# STM32F429 register map
File version: 1.8
CPU: CM4 r0p1, little endian, MPU, FPU, 4 interrupt priority bits
Registers are 32-bit, read-write, reset 0x0 unless marked. A register's access mark holds for its fields unless they carry their own. Offsets are from the block's base; [hi:lo] are bit positions; {n}, {i} and the like mark numbered series.

## I2C1 — Inter-integrated circuit
Base 0x40005400
Same registers: I2C2 0x40005800, I2C3 0x40005C00
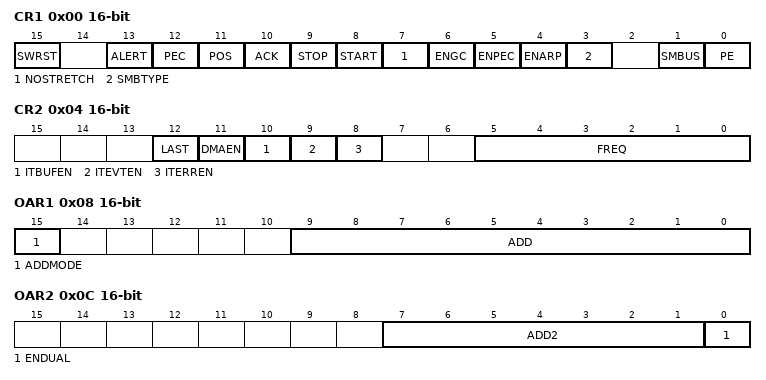
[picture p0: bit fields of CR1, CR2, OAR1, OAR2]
0x00 CR1 16-bit — Control register 1
  [15] SWRST — Software reset
    0=NotReset (I2C peripheral not under reset); 1=Reset (I2C peripheral under reset)
  [13] ALERT — SMBus alert
    0=Release (SMBA pin released high); 1=Drive (SMBA pin driven low)
  [12] PEC — Packet error checking
    0=Disabled (No PEC transfer); 1=Enabled (PEC transfer)
  [11] POS — Acknowledge/PEC Position (for data reception)
    0=Current (ACK bit controls the (N)ACK of the current byte being received); 1=Next (ACK bit controls the (N)ACK of the next byte to be received)
  [10] ACK — Acknowledge enable
    0=NAK (No acknowledge returned); 1=ACK (Acknowledge returned after a byte is received)
  [9] STOP — Stop generation
    0=No Stop generation; 1=Stop (In master mode: stop generation after current byte/start, in slave mode: release SCL and SDA after current byte)
  [8] START — Start generation
    0=No Start generation; 1=Start (In master mode: repeated start generation, in slave mode: start generation when bus is free)
  [7] NOSTRETCH — Clock stretching disable (Slave mode)
    0=Enabled (Clock stretching enabled); 1=Disabled (Clock stretching disabled)
  [6] ENGC — General call enable
    0=Disabled (General call disabled); 1=Enabled (General call enabled)
  [5] ENPEC — PEC enable
    0=Disabled (PEC calculation disabled); 1=Enabled (PEC calculation enabled)
  [4] ENARP — ARP enable
    0=Disabled (ARP disabled); 1=Enabled (ARP enabled)
  [3] SMBTYPE — SMBus type
    0=Device (SMBus Device); 1=Host (SMBus Host)
  [1] SMBUS — SMBus mode
    0=I2C (I2C Mode); 1=SMBus
  [0] PE — Peripheral enable
    0=Disabled (Peripheral disabled); 1=Enabled (Peripheral enabled)
0x04 CR2 16-bit — Control register 2
  [12] LAST — DMA last transfer
    0=NotLast (Next DMA EOT is not the last transfer); 1=Last (Next DMA EOT is the last transfer)
  [11] DMAEN — DMA requests enable
    0=Disabled (DMA requests disabled); 1=Enabled (DMA request enabled when TxE=1 or RxNE=1)
  [10] ITBUFEN — Buffer interrupt enable
    0=Disabled (TxE=1 or RxNE=1 does not generate any interrupt); 1=Enabled (TxE=1 or RxNE=1 generates Event interrupt)
  [9] ITEVTEN — Event interrupt enable
    0=Disabled (Event interrupt disabled); 1=Enabled (Event interrupt enabled)
  [8] ITERREN — Error interrupt enable
    0=Disabled (Error interrupt disabled); 1=Enabled (Error interrupt enabled)
  [5:0] FREQ range 2..50 — Peripheral clock frequency
0x08 OAR1 16-bit — Own address register 1
  [15] ADDMODE — Addressing mode (slave mode)
    0=ADD7 (7-bit slave address); 1=ADD10 (10-bit slave address)
  [9:0] ADD — Interface address
0x0C OAR2 16-bit — Own address register 2
  [7:1] ADD2 — Interface address
  [0] ENDUAL — Dual addressing mode enable
    0=Single addressing mode; 1=Dual addressing mode
0x10 DR 16-bit — Data register
  [7:0] DR — 8-bit data register
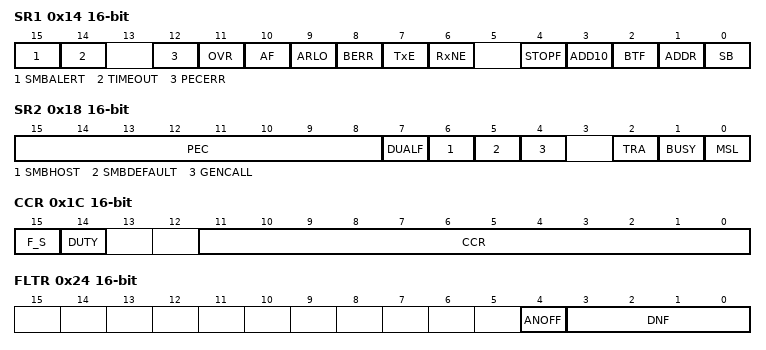
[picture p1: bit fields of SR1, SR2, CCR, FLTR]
0x14 SR1 16-bit access per field — Status register 1
  [15] SMBALERT rw write-0-clears — SMBus alert
    on read: 0=NoAlert (No SMBALERT occured); 1=Alert (SMBALERT occurred) | on write: 0=Clear flag
  [14] TIMEOUT rw write-0-clears — Timeout or Tlow error
    on read: 0=No Timeout error; 1=Timeout (SCL remained LOW for 25 ms) | on write: 0=Clear flag
  [12] PECERR rw write-0-clears — PEC Error in reception
    on read: 0=NoError (no PEC error: receiver returns ACK after PEC reception (if ACK=1)); 1=Error (PEC error: receiver returns NACK after PEC reception (whatever ACK)) | on write: 0=Clear flag
  [11] OVR rw write-0-clears — Overrun/Underrun
    on read: 0=No overrun/underrun occured; 1=Overrun/underrun occured | on write: 0=Clear flag
  [10] AF rw write-0-clears — Acknowledge failure
    on read: 0=NoFailure (No acknowledge failure); 1=Failure (Acknowledge failure) | on write: 0=Clear flag
  [9] ARLO rw write-0-clears — Arbitration lost (master mode)
    on read: 0=NoLost (No Arbitration Lost detected); 1=Lost (Arbitration Lost detected) | on write: 0=Clear flag
  [8] BERR rw write-0-clears — Bus error
    on read: 0=NoError (No misplaced Start or Stop condition); 1=Error (Misplaced Start or Stop condition) | on write: 0=Clear flag
  [7] TxE ro — Data register empty (transmitters)
    0=NotEmpty (Data register not empty); 1=Empty (Data register empty)
  [6] RxNE ro — Data register not empty (receivers)
    0=Empty (Data register empty); 1=NotEmpty (Data register not empty)
  [4] STOPF ro — Stop detection (slave mode)
    0=No Stop condition detected; 1=Stop condition detected
  [3] ADD10 ro — 10-bit header sent (Master mode)
  [2] BTF ro — Byte transfer finished
    0=NotFinished (Data byte transfer not done); 1=Finished (Data byte transfer successful)
  [1] ADDR ro — Address sent (master mode)/matched (slave mode)
    0=NotMatch (Adress mismatched or not received); 1=Match (Received slave address matched with one of the enabled slave addresses)
  [0] SB ro — Start bit (Master mode)
    0=No Start condition; 1=Start condition generated
0x18 SR2 16-bit ro — Status register 2
  [15:8] PEC — acket error checking register
  [7] DUALF — Dual flag (Slave mode)
  [6] SMBHOST — SMBus host header (Slave mode)
  [5] SMBDEFAULT — SMBus device default address (Slave mode)
  [4] GENCALL — General call address (Slave mode)
  [2] TRA — Transmitter/receiver
  [1] BUSY — Bus busy
  [0] MSL — Master/slave
0x1C CCR 16-bit — Clock control register
  [15] F_S — I2C master mode selection
    0=Standard mode I2C; 1=Fast mode I2C
  [14] DUTY — Fast mode duty cycle
    0=Duty2_1 (Duty cycle t_low/t_high = 2/1); 1=Duty16_9 (Duty cycle t_low/t_high = 16/9)
  [11:0] CCR range 1..4095 — Clock control register in Fast/Standard mode (Master mode)
0x20 TRISE 16-bit reset 0x2
  [5:0] TRISE — Maximum rise time in Fast/Standard mode (Master mode)
0x24 FLTR 16-bit — I2C FLTR register
  [4] ANOFF — Analog noise filter OFF
    0=Enabled (Analog noise filter enabled); 1=Disabled (Analog noise filter disabled)
  [3:0] DNF — Digital noise filter
    0=NoFilter (Digital filter disabled); {v}=Filter{v} (Digital filter enabled and filtering capability up to {v} tI2CCLK) (v=1..15)
